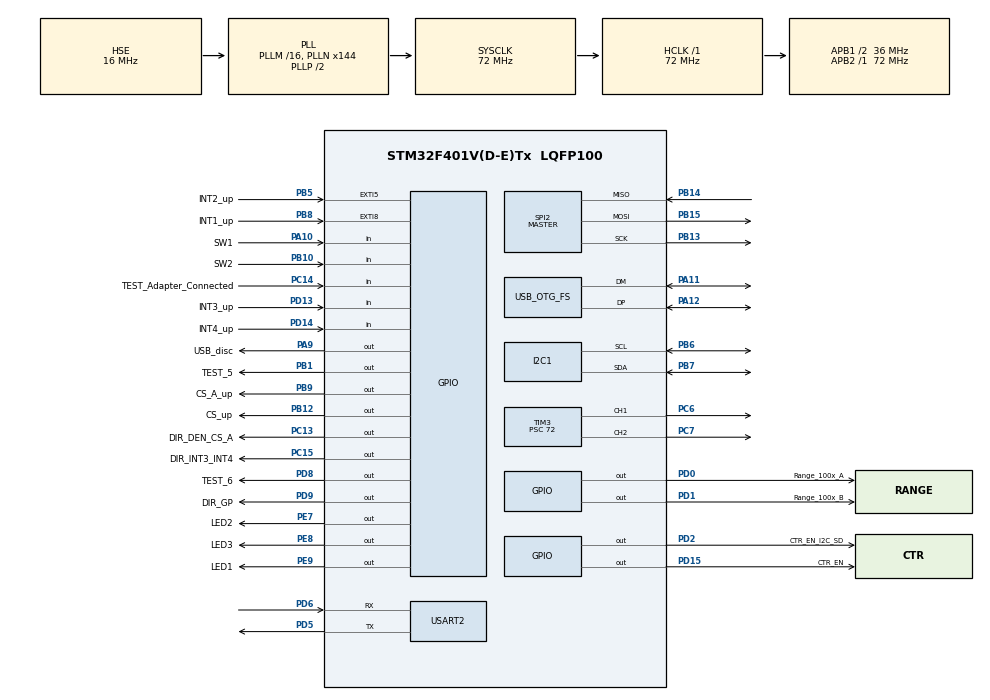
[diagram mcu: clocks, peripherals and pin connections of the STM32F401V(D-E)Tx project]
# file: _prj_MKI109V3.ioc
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I2C1.I2C_Mode=I2C_Fast
Mcu.Family=STM32F4
Mcu.Name=STM32F401V(D-E)Tx
Mcu.Package=LQFP100
NVIC.EXTI9_5_IRQn=true\:0\:0\:false\:false\:true\:true\:true\:true
NVIC.I2C1_EV_IRQn=true\:0\:0\:false\:false\:true\:true\:true\:true
NVIC.OTG_FS_IRQn=true\:0\:0\:false\:false\:true\:false\:true\:true
NVIC.PriorityGroup=NVIC_PRIORITYGROUP_4
PA10.GPIO_Label=SW1
PA10.Signal=GPIO_Input
PA11.Mode=Device_Only
PA11.Signal=USB_OTG_FS_DM
PA12.Mode=Device_Only
PA12.Signal=USB_OTG_FS_DP
PA9.GPIO_Label=USB_disc
PA9.PinState=GPIO_PIN_RESET
PA9.Signal=GPIO_Output
PB1.GPIO_Label=TEST_5
PB1.Signal=GPIO_Output
PB10.GPIO_Label=SW2
PB10.Signal=GPIO_Input
PB12.GPIO_Label=CS_up
PB12.GPIO_Speed=GPIO_SPEED_FREQ_VERY_HIGH
PB12.PinState=GPIO_PIN_SET
PB12.Signal=GPIO_Output
PB13.Mode=Full_Duplex_Master
PB13.Signal=SPI2_SCK
PB14.Mode=Full_Duplex_Master
PB14.Signal=SPI2_MISO
PB15.Mode=Full_Duplex_Master
PB15.Signal=SPI2_MOSI
PB5.GPIO_Label=INT2_up
PB5.Signal=GPXTI5
PB6.GPIO_Pu=GPIO_PULLUP
PB6.Mode=I2C
PB6.Signal=I2C1_SCL
PB7.GPIO_Pu=GPIO_PULLUP
PB7.Mode=I2C
PB7.Signal=I2C1_SDA
PB8.GPIO_Label=INT1_up
PB8.Signal=GPXTI8
PB9.GPIO_Label=CS_A_up
PB9.GPIO_PuPd=GPIO_NOPULL
PB9.GPIO_Speed=GPIO_SPEED_FREQ_VERY_HIGH
PB9.PinState=GPIO_PIN_SET
PB9.Signal=GPIO_Output
PC13-ANTI_TAMP.GPIO_Label=DIR_DEN_CS_A
PC13-ANTI_TAMP.PinState=GPIO_PIN_SET
PC13-ANTI_TAMP.Signal=GPIO_Output
PC14-OSC32_IN.GPIO_Label=TEST_Adapter_Connected
PC14-OSC32_IN.Signal=GPIO_Input
PC15-OSC32_OUT.GPIO_Label=DIR_INT3_INT4
PC15-OSC32_OUT.Signal=GPIO_Output
PC6.Signal=S_TIM3_CH1
PC7.Signal=S_TIM3_CH2
PD0.GPIO_Label=Range_100x_A
PD0.Signal=GPIO_Output
PD1.GPIO_Label=Range_100x_B
PD1.Signal=GPIO_Output
PD13.GPIO_Label=INT3_up
PD13.Signal=GPIO_Input
PD14.GPIO_Label=INT4_up
PD14.Signal=GPIO_Input
PD15.GPIO_Label=CTR_EN
PD15.Signal=GPIO_Output
PD2.GPIO_Label=CTR_EN_I2C_SD
PD2.PinState=GPIO_PIN_SET
PD2.Signal=GPIO_Output
PD5.Mode=Asynchronous
PD5.Signal=USART2_TX
PD6.Mode=Asynchronous
PD6.Signal=USART2_RX
PD8.GPIO_Label=TEST_6
PD8.Signal=GPIO_Output
PD9.GPIO_Label=DIR_GP
PD9.Signal=GPIO_Output
PE7.GPIO_Label=LED2
PE7.Signal=GPIO_Output
PE8.GPIO_Label=LED3
PE8.Signal=GPIO_Output
PE9.GPIO_Label=LED1
PE9.Signal=GPIO_Output
PH0\ -\ OSC_IN.Mode=HSE-External-Oscillator
PH0\ -\ OSC_IN.Signal=RCC_OSC_IN
PH1\ -\ OSC_OUT.Mode=HSE-External-Oscillator
PH1\ -\ OSC_OUT.Signal=RCC_OSC_OUT
ProjectManager.HeapSize=0x1000
ProjectManager.StackSize=0x1000
ProjectManager.TargetToolchain=CMake
RCC.48MHZClocksFreq_Value=48000000
RCC.AHBFreq_Value=72000000
RCC.APB1CLKDivider=RCC_HCLK_DIV2
RCC.APB1Freq_Value=36000000
RCC.APB1TimFreq_Value=72000000
RCC.APB2Freq_Value=72000000
RCC.APB2TimFreq_Value=72000000
RCC.CortexFreq_Value=72000000
RCC.HCLKFreq_Value=72000000
RCC.HSE_VALUE=16000000
RCC.HSI_VALUE=16000000
RCC.LSE_VALUE=32768
RCC.PLLN=144
RCC.PLLQ=3
RCC.SYSCLKFreq_VALUE=72000000
RCC.SYSCLKSource=RCC_SYSCLKSOURCE_PLLCLK
RCC.VCOOutputFreq_Value=144000000
SH.S_TIM3_CH1.0=TIM3_CH1,PWM Generation1 CH1
SH.S_TIM3_CH2.0=TIM3_CH2,PWM Generation2 CH2
SPI2.BaudRatePrescaler=SPI_BAUDRATEPRESCALER_4
SPI2.CLKPhase=SPI_PHASE_2EDGE
SPI2.CLKPolarity=SPI_POLARITY_HIGH
SPI2.Direction=SPI_DIRECTION_2LINES
SPI2.Mode=SPI_MODE_MASTER
SPI2.VirtualType=VM_MASTER
TIM3.Channel-PWM\ Generation1\ CH1=TIM_CHANNEL_1
TIM3.Channel-PWM\ Generation2\ CH2=TIM_CHANNEL_2
TIM3.Period=1000
TIM3.Prescaler=72
TIM3.Pulse-PWM\ Generation1\ CH1=700
TIM3.Pulse-PWM\ Generation2\ CH2=700
USART2.VirtualMode=VM_ASYNC
USB_DEVICE.CLASS_NAME_FS=CDC
USB_DEVICE.VirtualMode-CDC_FS=Cdc
USB_DEVICE.VirtualModeFS=Cdc_FS
USB_OTG_FS.VirtualMode=Device_Only
VP_TIM3_VS_ClockSourceINT.Mode=Internal
VP_USB_DEVICE_VS_USB_DEVICE_CDC_FS.Mode=CDC_FS
board=MKI109V3

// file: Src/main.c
/* USER CODE BEGIN Header */
/**
  ******************************************************************************
  * @file           : main.c
  * @brief          : Main program body
  ******************************************************************************
  * @attention
  *
  * Copyright (c) 2024 STMicroelectronics.
  * All rights reserved.
  *
  * This software is licensed under terms that can be found in the LICENSE file
  * in the root directory of this software component.
  * If no LICENSE file comes with this software, it is provided AS-IS.
  *
  ******************************************************************************
  */
/* USER CODE END Header */
#include "main.h"
#include "i2c.h"
#include "spi.h"
#include "tim.h"
#include "usart.h"
#include "usb_device.h"
#include "gpio.h"

void SystemClock_Config(void);
/* USER CODE BEGIN PFP */
void asm330lhhxg1_read_data_polling(void);
/* USER CODE END PFP */

int main(void)
{

  /* MCU Configuration--------------------------------------------------------*/

  /* Reset of all peripherals, Initializes the Flash interface and the Systick. */
  HAL_Init();

  /* Configure the system clock */
  SystemClock_Config();

  /* Initialize all configured peripherals */
  MX_GPIO_Init();
  MX_I2C1_Init();
  MX_SPI2_Init();
  MX_USB_DEVICE_Init();
  MX_USART2_UART_Init();
  MX_TIM3_Init();

  /* Infinite loop */
  /* USER CODE BEGIN WHILE */
  while (1)
  {
    asm330lhhxg1_read_data_polling();
    /* USER CODE END WHILE */

  }
}

void SystemClock_Config(void)
{
  RCC_OscInitTypeDef RCC_OscInitStruct = {0};
  RCC_ClkInitTypeDef RCC_ClkInitStruct = {0};

  /** Configure the main internal regulator output voltage
  */
  __HAL_RCC_PWR_CLK_ENABLE();
  __HAL_PWR_VOLTAGESCALING_CONFIG(PWR_REGULATOR_VOLTAGE_SCALE2);

  /** Initializes the RCC Oscillators according to the specified parameters
  * in the RCC_OscInitTypeDef structure.
  */
  RCC_OscInitStruct.OscillatorType = RCC_OSCILLATORTYPE_HSE;
  RCC_OscInitStruct.HSEState = RCC_HSE_ON;
  RCC_OscInitStruct.PLL.PLLState = RCC_PLL_ON;
  RCC_OscInitStruct.PLL.PLLSource = RCC_PLLSOURCE_HSE;
  RCC_OscInitStruct.PLL.PLLM = 16;
  RCC_OscInitStruct.PLL.PLLN = 144;
  RCC_OscInitStruct.PLL.PLLP = RCC_PLLP_DIV2;
  RCC_OscInitStruct.PLL.PLLQ = 3;
  if (HAL_RCC_OscConfig(&RCC_OscInitStruct) != HAL_OK)
  {
    Error_Handler();
  }

  /** Initializes the CPU, AHB and APB buses clocks
  */
  RCC_ClkInitStruct.ClockType = RCC_CLOCKTYPE_HCLK|RCC_CLOCKTYPE_SYSCLK
                              |RCC_CLOCKTYPE_PCLK1|RCC_CLOCKTYPE_PCLK2;
  RCC_ClkInitStruct.SYSCLKSource = RCC_SYSCLKSOURCE_PLLCLK;
  RCC_ClkInitStruct.AHBCLKDivider = RCC_SYSCLK_DIV1;
  RCC_ClkInitStruct.APB1CLKDivider = RCC_HCLK_DIV2;
  RCC_ClkInitStruct.APB2CLKDivider = RCC_HCLK_DIV1;

  if (HAL_RCC_ClockConfig(&RCC_ClkInitStruct, FLASH_LATENCY_2) != HAL_OK)
  {
    Error_Handler();
  }
}

void Error_Handler(void)
{
  __disable_irq();
  while (1)
  {
  }
}
